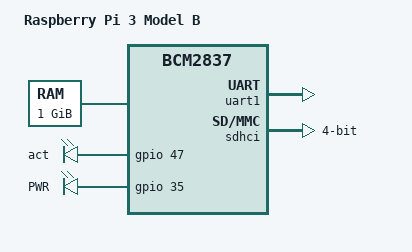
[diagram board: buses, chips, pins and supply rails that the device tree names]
/dts-v1/;

/memreserve/ 0x00000000 0x00001000;

#include "bcm2837.dtsi"

/ {
	compatible = "raspberrypi,3-model-b", "brcm,bcm2837";
	model = "Raspberry Pi 3 Model B";

	chosen {
		bootargs = "earlyprintk console=ttyS0 8250.nr_uarts=1";
	};

	memory {
		reg = <0 0x40000000>;
	};

	leds {
		act {
			gpios = <&gpio 47 0>;
		};

		pwr {
			label = "PWR";
			gpios = <&gpio 35 0>;
			default-state = "keep";
			linux,default-trigger = "default-on";
		};
	};

	soc {
                uart1: uart@7e215040 {
                        compatible = "brcm,bcm2835-aux-uart", "ns16550";
                        reg = <0x7e215040 0x40>;
                        interrupts = <1 29>;
                        clock-frequency = <500000000>;
                        reg-shift = <2>;
                        no-loopback-test;
                };
	};
};

&gpio {
	pinctrl-0 = <&gpioout &alt0 &i2s_alt0 &alt3>;

	gpioout: gpioout {
		brcm,pins = <6>;
		brcm,function = <BCM2835_FSEL_GPIO_OUT>;
	};

	alt0: alt0 {
		brcm,pins = <0 1 2 3 4 5 7 8 9 10 11 14 15 40 45>;
		brcm,function = <BCM2835_FSEL_ALT0>;
	};

	/* I2S interface */
	i2s_alt0: i2s_alt0 {
		brcm,pins = <18 19 20 21>;
		brcm,function = <BCM2835_FSEL_ALT0>;
	};

	alt3: alt3 {
		brcm,pins = <48 49 50 51 52 53>;
		brcm,function = <BCM2835_FSEL_ALT3>;
	};
};

&sdhci {
        bus-width = <4>;
        status = "okay";
};

&v8_cpu1 {
	enable-method = "spin-table";
	cpu-release-addr = <0 0x000000e0>;
};

&v8_cpu2 {
	enable-method = "spin-table";
	cpu-release-addr = <0 0x000000e8>;
};

&v8_cpu3 {
	enable-method = "spin-table";
	cpu-release-addr = <0 0x000000f0>;
};
